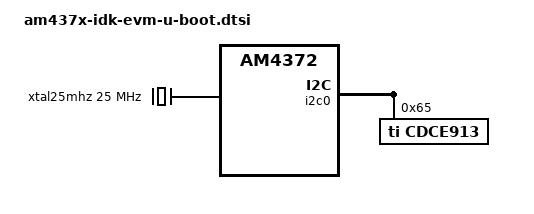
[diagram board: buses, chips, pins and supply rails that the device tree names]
// SPDX-License-Identifier: GPL-2.0+
/*
 * Copyright (C) 2018 Texas Instruments Incorporated - https://www.ti.com/
 */

#include "am4372-u-boot.dtsi"

/{
	ocp {
		bootph-pre-ram;
	};

	xtal25mhz: xtal25mhz {
		compatible = "fixed-clock";
		#clock-cells = <0>;
		clock-frequency = <25000000>;
	};
};

&uart0 {
	bootph-pre-ram;
};

&i2c0 {
	bootph-pre-ram;

	cdce913: cdce913@65 {
		compatible = "ti,cdce913";
		reg = <0x65>;
		clocks = <&xtal25mhz>;
		#clock-cells = <1>;
		xtal-load-pf = <0>;
	};
};

&mmc1 {
	bootph-pre-ram;
};
